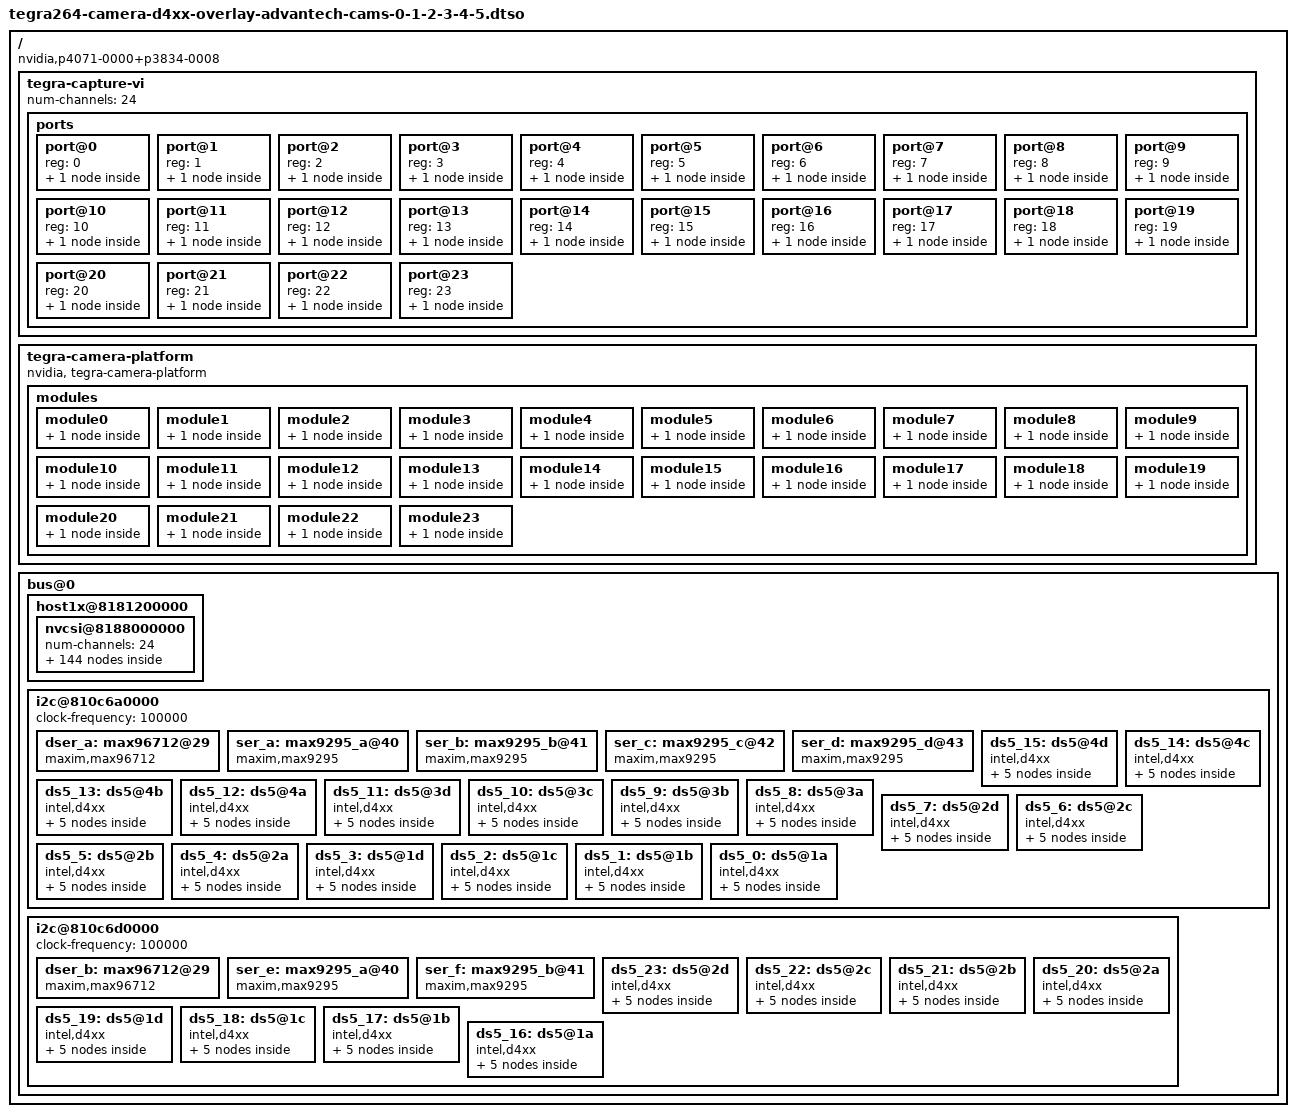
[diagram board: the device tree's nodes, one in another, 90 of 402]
// SPDX-License-Identifier: GPL-2.0-only
// SPDX-FileCopyrightText: Copyright (c) 2018-2023, INTEL CORPORATION.  All rights reserved.

/dts-v1/;
/plugin/;

#include <dt-bindings/gpio/tegra264-gpio.h>

/* camera control gpio definitions */
/ {
	overlay-name = "Jetson six RealSense Cameras D4xx with max96712 Advantech for Thor";
	jetson-header-name = "Jetson AGX CSI Connector";
	compatible = "nvidia,p4071-0000+p3834-0008", "nvidia,p3834-0008", "nvidia,tegra264";

	fragment@0 {
		target-path = "/";
		__overlay__ {
			tegra-capture-vi {
				num-channels = <24>;
				ports {
					status = "okay";
					/* ---- Cameras 0-3 (i2c9 / dser_a) ---- */
					port@0 {
						status = "okay";
						reg = <0>;
						d4xx_vi_in0: endpoint {
							status = "okay";
							vc-id = <0>;
							port-index = <0>;
							bus-width = <2>;
							remote-endpoint = <&d4xx_csi_out0>;
						};
					};
					port@1 {
						status = "okay";
						reg = <1>;
						d4xx_vi_in1: endpoint {
							status = "okay";
							vc-id = <1>;
							port-index = <0>;
							bus-width = <2>;
							remote-endpoint = <&d4xx_csi_out1>;
						};
					};
					port@2 {
						status = "okay";
						reg = <2>;
						d4xx_vi_in2: endpoint {
							status = "okay";
							vc-id = <2>;
							port-index = <0>;
							bus-width = <2>;
							remote-endpoint = <&d4xx_csi_out2>;
						};
					};
					port@3 {
						status = "okay";
						reg = <3>;
						d4xx_vi_in3: endpoint {
							status = "okay";
							vc-id = <3>;
							port-index = <0>;
							bus-width = <2>;
							remote-endpoint = <&d4xx_csi_out3>;
						};
					};
					port@4 {
						status = "okay";
						reg = <4>;
						d4xx_vi_in4: endpoint {
							status = "okay";
							vc-id = <4>;
							port-index = <0>;
							bus-width = <2>;
							remote-endpoint = <&d4xx_csi_out4>;
						};
					};
					port@5 {
						status = "okay";
						reg = <5>;
						d4xx_vi_in5: endpoint {
							status = "okay";
							vc-id = <5>;
							port-index = <0>;
							bus-width = <2>;
							remote-endpoint = <&d4xx_csi_out5>;
						};
					};
					port@6 {
						status = "okay";
						reg = <6>;
						d4xx_vi_in6: endpoint {
							status = "okay";
							vc-id = <6>;
							port-index = <0>;
							bus-width = <2>;
							remote-endpoint = <&d4xx_csi_out6>;
						};
					};
					port@7 {
						status = "okay";
						reg = <7>;
						d4xx_vi_in7: endpoint {
							status = "okay";
							vc-id = <7>;
							port-index = <0>;
							bus-width = <2>;
							remote-endpoint = <&d4xx_csi_out7>;
						};
					};
					port@8 {
						status = "okay";
						reg = <8>;
						d4xx_vi_in8: endpoint {
							status = "okay";
							vc-id = <8>;
							port-index = <0>;
							bus-width = <2>;
							remote-endpoint = <&d4xx_csi_out8>;
						};
					};
					port@9 {
						status = "okay";
						reg = <9>;
						d4xx_vi_in9: endpoint {
							status = "okay";
							vc-id = <9>;
							port-index = <0>;
							bus-width = <2>;
							remote-endpoint = <&d4xx_csi_out9>;
						};
					};
					port@10 {
						status = "okay";
						reg = <10>;
						d4xx_vi_in10: endpoint {
							status = "okay";
							vc-id = <10>;
							port-index = <0>;
							bus-width = <2>;
							remote-endpoint = <&d4xx_csi_out10>;
						};
					};
					port@11 {
						status = "okay";
						reg = <11>;
						d4xx_vi_in11: endpoint {
							status = "okay";
							vc-id = <11>;
							port-index = <0>;
							bus-width = <2>;
							remote-endpoint = <&d4xx_csi_out11>;
						};
					};
					port@12 {
						status = "okay";
						reg = <12>;
						d4xx_vi_in12: endpoint {
							status = "okay";
							vc-id = <12>;
							port-index = <0>;
							bus-width = <2>;
							remote-endpoint = <&d4xx_csi_out12>;
						};
					};
					port@13 {
						status = "okay";
						reg = <13>;
						d4xx_vi_in13: endpoint {
							status = "okay";
							vc-id = <13>;
							port-index = <0>;
							bus-width = <2>;
							remote-endpoint = <&d4xx_csi_out13>;
						};
					};
					port@14 {
						status = "okay";
						reg = <14>;
						d4xx_vi_in14: endpoint {
							status = "okay";
							vc-id = <14>;
							port-index = <0>;
							bus-width = <2>;
							remote-endpoint = <&d4xx_csi_out14>;
						};
					};
					port@15 {
						status = "okay";
						reg = <15>;
						d4xx_vi_in15: endpoint {
							status = "okay";
							vc-id = <15>;
							port-index = <0>;
							bus-width = <2>;
							remote-endpoint = <&d4xx_csi_out15>;
						};
					};
					/* ---- Cameras 4-5 (i2c12 / dser_b) ---- */
					port@16 {
						status = "okay";
						reg = <16>;
						d4xx_vi_in16: endpoint {
							status = "okay";
							vc-id = <0>;
							port-index = <4>;
							bus-width = <2>;
							remote-endpoint = <&d4xx_csi_out16>;
						};
					};
					port@17 {
						status = "okay";
						reg = <17>;
						d4xx_vi_in17: endpoint {
							status = "okay";
							vc-id = <1>;
							port-index = <4>;
							bus-width = <2>;
							remote-endpoint = <&d4xx_csi_out17>;
						};
					};
					port@18 {
						status = "okay";
						reg = <18>;
						d4xx_vi_in18: endpoint {
							status = "okay";
							vc-id = <2>;
							port-index = <4>;
							bus-width = <2>;
							remote-endpoint = <&d4xx_csi_out18>;
						};
					};
					port@19 {
						status = "okay";
						reg = <19>;
						d4xx_vi_in19: endpoint {
							status = "okay";
							vc-id = <3>;
							port-index = <4>;
							bus-width = <2>;
							remote-endpoint = <&d4xx_csi_out19>;
						};
					};
					port@20 {
						status = "okay";
						reg = <20>;
						d4xx_vi_in20: endpoint {
							status = "okay";
							vc-id = <4>;
							port-index = <4>;
							bus-width = <2>;
							remote-endpoint = <&d4xx_csi_out20>;
						};
					};
					port@21 {
						status = "okay";
						reg = <21>;
						d4xx_vi_in21: endpoint {
							status = "okay";
							vc-id = <5>;
							port-index = <4>;
							bus-width = <2>;
							remote-endpoint = <&d4xx_csi_out21>;
						};
					};
					port@22 {
						status = "okay";
						reg = <22>;
						d4xx_vi_in22: endpoint {
							status = "okay";
							vc-id = <6>;
							port-index = <4>;
							bus-width = <2>;
							remote-endpoint = <&d4xx_csi_out22>;
						};
					};
					port@23 {
						status = "okay";
						reg = <23>;
						d4xx_vi_in23: endpoint {
							status = "okay";
							vc-id = <7>;
							port-index = <4>;
							bus-width = <2>;
							remote-endpoint = <&d4xx_csi_out23>;
						};
					};
				};
			};
			tegra-camera-platform {
				compatible = "nvidia, tegra-camera-platform";
				status = "okay";
				num_csi_lanes = <2>;
				max_lane_speed = <1500000>;
				min_bits_per_pixel = <8>;
				vi_peak_byte_per_pixel = <2>;
				vi_bw_margin_pct = <25>;
				max_pixel_rate = <160000>;
				isp_peak_byte_per_pixel = <5>;
				isp_bw_margin_pct = <25>;
				modules {
					status = "okay";
					/* ---- Cameras 0-3 (i2c9) ---- */
					module0 {
						status = "okay";
						badge = "d4xx_depth";
						position = "left";
						orientation = "1";
						drivernode0 {
							status = "okay";
							pcl_id = "v4l2_sensor";
							devname = "DS5 mux 9-001a";
							sysfs-device-tree = "/sys/firmware/devicetree/base/bus@0/i2c@810c6a0000/ds5@1a";
						};
					};
					module1 {
						status = "okay";
						badge = "d4xx_rgb";
						position = "left";
						orientation = "1";
						drivernode0 {
							status = "okay";
							pcl_id = "v4l2_sensor";
							devname = "DS5 mux 9-001b";
							sysfs-device-tree = "/sys/firmware/devicetree/base/bus@0/i2c@810c6a0000/ds5@1b";
						};
					};
					module2 {
						status = "okay";
						badge = "d4xx_Y8";
						position = "left";
						orientation = "1";
						drivernode0 {
							status = "okay";
							pcl_id = "v4l2_sensor";
							devname = "DS5 mux 9-001c";
							sysfs-device-tree = "/sys/firmware/devicetree/base/bus@0/i2c@810c6a0000/ds5@1c";
						};
					};
					module3 {
						status = "okay";
						badge = "d4xx_imu";
						position = "left";
						orientation = "1";
						drivernode0 {
							status = "okay";
							pcl_id = "v4l2_sensor";
							devname = "DS5 mux 9-001d";
							sysfs-device-tree = "/sys/firmware/devicetree/base/bus@0/i2c@810c6a0000/ds5@1d";
						};
					};
					module4 {
						status = "okay";
						badge = "d4xx_depth";
						position = "center";
						orientation = "1";
						drivernode0 {
							status = "okay";
							pcl_id = "v4l2_sensor";
							devname = "DS5 mux 9-002a";
							sysfs-device-tree = "/sys/firmware/devicetree/base/bus@0/i2c@810c6a0000/ds5@2a";
						};
					};
					module5 {
						status = "okay";
						badge = "d4xx_rgb";
						position = "center";
						orientation = "1";
						drivernode0 {
							status = "okay";
							pcl_id = "v4l2_sensor";
							devname = "DS5 mux 9-002b";
							sysfs-device-tree = "/sys/firmware/devicetree/base/bus@0/i2c@810c6a0000/ds5@2b";
						};
					};
					module6 {
						status = "okay";
						badge = "d4xx_Y8";
						position = "center";
						orientation = "1";
						drivernode0 {
							status = "okay";
							pcl_id = "v4l2_sensor";
							devname = "DS5 mux 9-002c";
							sysfs-device-tree = "/sys/firmware/devicetree/base/bus@0/i2c@810c6a0000/ds5@2c";
						};
					};
					module7 {
						status = "okay";
						badge = "d4xx_imu";
						position = "center";
						orientation = "1";
						drivernode0 {
							status = "okay";
							pcl_id = "v4l2_sensor";
							devname = "DS5 mux 9-002d";
							sysfs-device-tree = "/sys/firmware/devicetree/base/bus@0/i2c@810c6a0000/ds5@2d";
						};
					};
					module8 {
						status = "okay";
						badge = "d4xx_depth";
						position = "right";
						orientation = "1";
						drivernode0 {
							status = "okay";
							pcl_id = "v4l2_sensor";
							devname = "DS5 mux 9-003a";
							sysfs-device-tree = "/sys/firmware/devicetree/base/bus@0/i2c@810c6a0000/ds5@3a";
						};
					};
					module9 {
						status = "okay";
						badge = "d4xx_rgb";
						position = "right";
						orientation = "1";
						drivernode0 {
							status = "okay";
							pcl_id = "v4l2_sensor";
							devname = "DS5 mux 9-003b";
							sysfs-device-tree = "/sys/firmware/devicetree/base/bus@0/i2c@810c6a0000/ds5@3b";
						};
					};
					module10 {
						status = "okay";
						badge = "d4xx_Y8";
						position = "right";
						orientation = "1";
						drivernode0 {
							status = "okay";
							pcl_id = "v4l2_sensor";
							devname = "DS5 mux 9-003c";
							sysfs-device-tree = "/sys/firmware/devicetree/base/bus@0/i2c@810c6a0000/ds5@3c";
						};
					};
					module11 {
						status = "okay";
						badge = "d4xx_imu";
						position = "right";
						orientation = "1";
						drivernode0 {
							status = "okay";
							pcl_id = "v4l2_sensor";
							devname = "DS5 mux 9-003d";
							sysfs-device-tree = "/sys/firmware/devicetree/base/bus@0/i2c@810c6a0000/ds5@3d";
						};
					};
					module12 {
						status = "okay";
						badge = "d4xx_depth";
						position = "rear";
						orientation = "1";
						drivernode0 {
							status = "okay";
							pcl_id = "v4l2_sensor";
							devname = "DS5 mux 9-004a";
							sysfs-device-tree = "/sys/firmware/devicetree/base/bus@0/i2c@810c6a0000/ds5@4a";
						};
					};
					module13 {
						status = "okay";
						badge = "d4xx_rgb";
						position = "rear";
						orientation = "1";
						drivernode0 {
							status = "okay";
							pcl_id = "v4l2_sensor";
							devname = "DS5 mux 9-004b";
							sysfs-device-tree = "/sys/firmware/devicetree/base/bus@0/i2c@810c6a0000/ds5@4b";
						};
					};
					module14 {
						status = "okay";
						badge = "d4xx_Y8";
						position = "rear";
						orientation = "1";
						drivernode0 {
							status = "okay";
							pcl_id = "v4l2_sensor";
							devname = "DS5 mux 9-004c";
							sysfs-device-tree = "/sys/firmware/devicetree/base/bus@0/i2c@810c6a0000/ds5@4c";
						};
					};
					module15 {
						status = "okay";
						badge = "d4xx_imu";
						position = "rear";
						orientation = "1";
						drivernode0 {
							status = "okay";
							pcl_id = "v4l2_sensor";
							devname = "DS5 mux 9-004d";
							sysfs-device-tree = "/sys/firmware/devicetree/base/bus@0/i2c@810c6a0000/ds5@4d";
						};
					};
					/* ---- Cameras 4-5 (i2c12) ---- */
					module16 {
						status = "okay";
						badge = "d4xx_depth";
						position = "front-left";
						orientation = "1";
						drivernode0 {
							status = "okay";
							pcl_id = "v4l2_sensor";
							devname = "DS5 mux 12-001a";
							sysfs-device-tree = "/sys/firmware/devicetree/base/bus@0/i2c@810c6d0000/ds5@1a";
						};
					};
					module17 {
						status = "okay";
						badge = "d4xx_rgb";
						position = "front-left";
						orientation = "1";
						drivernode0 {
							status = "okay";
							pcl_id = "v4l2_sensor";
							devname = "DS5 mux 12-001b";
							sysfs-device-tree = "/sys/firmware/devicetree/base/bus@0/i2c@810c6d0000/ds5@1b";
						};
					};
					module18 {
						status = "okay";
						badge = "d4xx_Y8";
						position = "front-left";
						orientation = "1";
						drivernode0 {
							status = "okay";
							pcl_id = "v4l2_sensor";
							devname = "DS5 mux 12-001c";
							sysfs-device-tree = "/sys/firmware/devicetree/base/bus@0/i2c@810c6d0000/ds5@1c";
						};
					};
					module19 {
						status = "okay";
						badge = "d4xx_imu";
						position = "front-left";
						orientation = "1";
						drivernode0 {
							status = "okay";
							pcl_id = "v4l2_sensor";
							devname = "DS5 mux 12-001d";
							sysfs-device-tree = "/sys/firmware/devicetree/base/bus@0/i2c@810c6d0000/ds5@1d";
						};
					};
					module20 {
						status = "okay";
						badge = "d4xx_depth";
						position = "front-right";
						orientation = "1";
						drivernode0 {
							status = "okay";
							pcl_id = "v4l2_sensor";
							devname = "DS5 mux 12-002a";
							sysfs-device-tree = "/sys/firmware/devicetree/base/bus@0/i2c@810c6d0000/ds5@2a";
						};
					};
					module21 {
						status = "okay";
						badge = "d4xx_rgb";
						position = "front-right";
						orientation = "1";
						drivernode0 {
							status = "okay";
							pcl_id = "v4l2_sensor";
							devname = "DS5 mux 12-002b";
							sysfs-device-tree = "/sys/firmware/devicetree/base/bus@0/i2c@810c6d0000/ds5@2b";
						};
					};
					module22 {
						status = "okay";
						badge = "d4xx_Y8";
						position = "front-right";
						orientation = "1";
						drivernode0 {
							status = "okay";
							pcl_id = "v4l2_sensor";
							devname = "DS5 mux 12-002c";
							sysfs-device-tree = "/sys/firmware/devicetree/base/bus@0/i2c@810c6d0000/ds5@2c";
						};
					};
					module23 {
						status = "okay";
						badge = "d4xx_imu";
						position = "front-right";
						orientation = "1";
						drivernode0 {
							status = "okay";
							pcl_id = "v4l2_sensor";
							devname = "DS5 mux 12-002d";
							sysfs-device-tree = "/sys/firmware/devicetree/base/bus@0/i2c@810c6d0000/ds5@2d";
						};
					};
				};
			};
			bus@0 {
				host1x@8181200000 {
					nvcsi@8188000000 {
						num-channels = <24>;
						/* ---- Cameras 0-3 (i2c9 / dser_a) ---- */
						channel@0 {
							status = "okay";
							reg = <0>;
							ports {
								status = "okay";
								port@0 {
									status = "okay";
									reg = <0>;
									d4xx_csi_in0: endpoint@0 {
										status = "okay";
										port-index = <0>;
										bus-width = <2>;
										remote-endpoint = <&ds5_0_out>;
									};
								};
								port@1 {
									status = "okay";
									reg = <1>;
									d4xx_csi_out0: endpoint@1 {
										status = "okay";
										remote-endpoint = <&d4xx_vi_in0>;
									};
								};
							};
						};
						channel@1 {
							status = "okay";
							reg = <1>;
							ports {
								status = "okay";
								port@0 {
									status = "okay";
									reg = <0>;
									d4xx_csi_in1: endpoint@2 {
										status = "okay";
										port-index = <0>;
										bus-width = <2>;
										remote-endpoint = <&ds5_1_out>;
									};
								};
								port@1 {
									status = "okay";
									reg = <1>;
									d4xx_csi_out1: endpoint@3 {
										status = "okay";
										remote-endpoint = <&d4xx_vi_in1>;
									};
								};
							};
						};
						channel@2 {
							status = "okay";
							reg = <2>;
							ports {
								status = "okay";
								port@0 {
									status = "okay";
									reg = <0>;
									d4xx_csi_in2: endpoint@4 {
										status = "okay";
										port-index = <0>;
										bus-width = <2>;
										remote-endpoint = <&ds5_2_out>;
									};
								};
								port@1 {
									status = "okay";
									reg = <1>;
									d4xx_csi_out2: endpoint@5 {
										status = "okay";
										remote-endpoint = <&d4xx_vi_in2>;
									};
								};
							};
						};
						channel@3 {
							status = "okay";
							reg = <3>;
							ports {
								status = "okay";
								port@0 {
									status = "okay";
									reg = <0>;
									d4xx_csi_in3: endpoint@6 {
										status = "okay";
										port-index = <0>;
										bus-width = <2>;
										remote-endpoint = <&ds5_3_out>;
									};
								};
								port@1 {
									status = "okay";
									reg = <1>;
									d4xx_csi_out3: endpoint@7 {
										status = "okay";
										remote-endpoint = <&d4xx_vi_in3>;
									};
								};
							};
						};
						channel@4 {
							status = "okay";
							reg = <4>;
							ports {
								status = "okay";
								port@0 {
									status = "okay";
									reg = <0>;
									d4xx_csi_in4: endpoint@8 {
										status = "okay";
										port-index = <0>;
										bus-width = <2>;
										remote-endpoint = <&ds5_4_out>;
									};
								};
								port@1 {
									status = "okay";
									reg = <1>;
									d4xx_csi_out4: endpoint@9 {
										status = "okay";
										remote-endpoint = <&d4xx_vi_in4>;
									};
								};
							};
						};
						channel@5 {
							status = "okay";
							reg = <5>;
							ports {
								status = "okay";
								port@0 {
									status = "okay";
									reg = <0>;
									d4xx_csi_in5: endpoint@10 {
										status = "okay";
										port-index = <0>;
										bus-width = <2>;
										remote-endpoint = <&ds5_5_out>;
									};
								};
								port@1 {
									status = "okay";
									reg = <1>;
									d4xx_csi_out5: endpoint@11 {
										status = "okay";
										remote-endpoint = <&d4xx_vi_in5>;
									};
								};
							};
						};
						channel@6 {
							status = "okay";
							reg = <6>;
							ports {
								status = "okay";
								port@0 {
									status = "okay";
									reg = <0>;
									d4xx_csi_in6: endpoint@12 {
										status = "okay";
										port-index = <0>;
										bus-width = <2>;
										remote-endpoint = <&ds5_6_out>;
									};
								};
								port@1 {
									status = "okay";
									reg = <1>;
									d4xx_csi_out6: endpoint@13 {
										status = "okay";
										remote-endpoint = <&d4xx_vi_in6>;
									};
								};
							};
						};
						channel@7 {
							status = "okay";
							reg = <7>;
							ports {
								status = "okay";
								port@0 {
									status = "okay";
									reg = <0>;
									d4xx_csi_in7: endpoint@14 {
										status = "okay";
										port-index = <0>;
										bus-width = <2>;
										remote-endpoint = <&ds5_7_out>;
									};
								};
								port@1 {
									status = "okay";
									reg = <1>;
									d4xx_csi_out7: endpoint@15 {
										status = "okay";
										remote-endpoint = <&d4xx_vi_in7>;
									};
								};
							};
						};
						channel@8 {
							status = "okay";
							reg = <8>;
							ports {
								status = "okay";
								port@0 {
									status = "okay";
									reg = <0>;
									d4xx_csi_in8: endpoint@16 {
										status = "okay";
										port-index = <0>;
										bus-width = <2>;
										remote-endpoint = <&ds5_8_out>;
									};
								};
								port@1 {
									status = "okay";
									reg = <1>;
									d4xx_csi_out8: endpoint@17 {
										status = "okay";
										remote-endpoint = <&d4xx_vi_in8>;
									};
								};
							};
						};
						channel@9 {
							status = "okay";
							reg = <9>;
							ports {
								status = "okay";
								port@0 {
									status = "okay";
									reg = <0>;
									d4xx_csi_in9: endpoint@18 {
										status = "okay";
										port-index = <0>;
										bus-width = <2>;
										remote-endpoint = <&ds5_9_out>;
									};
								};
								port@1 {
									status = "okay";
									reg = <1>;
									d4xx_csi_out9: endpoint@19 {
										status = "okay";
										remote-endpoint = <&d4xx_vi_in9>;
									};
								};
							};
						};
						channel@10 {
							status = "okay";
							reg = <10>;
							ports {
								status = "okay";
								port@0 {
									status = "okay";
									reg = <0>;
									d4xx_csi_in10: endpoint@20 {
										status = "okay";
										port-index = <0>;
										bus-width = <2>;
										remote-endpoint = <&ds5_10_out>;
									};
								};
								port@1 {
									status = "okay";
									reg = <1>;
									d4xx_csi_out10: endpoint@21 {
										status = "okay";
										remote-endpoint = <&d4xx_vi_in10>;
									};
								};
							};
						};
						channel@11 {
							status = "okay";
							reg = <11>;
							ports {
								status = "okay";
								port@0 {
									status = "okay";
									reg = <0>;
									d4xx_csi_in11: endpoint@22 {
										status = "okay";
										port-index = <0>;
										bus-width = <2>;
										remote-endpoint = <&ds5_11_out>;
									};
								};
								port@1 {
									status = "okay";
									reg = <1>;
									d4xx_csi_out11: endpoint@23 {
										status = "okay";
										remote-endpoint = <&d4xx_vi_in11>;
									};
								};
							};
						};
						channel@12 {
							status = "okay";
							reg = <12>;
							ports {
								status = "okay";
								port@0 {
									status = "okay";
									reg = <0>;
									d4xx_csi_in12: endpoint@24 {
										status = "okay";
										port-index = <0>;
										bus-width = <2>;
										remote-endpoint = <&ds5_12_out>;
									};
								};
								port@1 {
									status = "okay";
									reg = <1>;
									d4xx_csi_out12: endpoint@25 {
										status = "okay";
										remote-endpoint = <&d4xx_vi_in12>;
									};
								};
							};
						};
						channel@13 {
							status = "okay";
							reg = <13>;
							ports {
								status = "okay";
								port@0 {
									status = "okay";
									reg = <0>;
									d4xx_csi_in13: endpoint@26 {
										status = "okay";
										port-index = <0>;
										bus-width = <2>;
										remote-endpoint = <&ds5_13_out>;
									};
								};
								port@1 {
									status = "okay";
									reg = <1>;
									d4xx_csi_out13: endpoint@27 {
										status = "okay";
										remote-endpoint = <&d4xx_vi_in13>;
									};
								};
							};
						};
						channel@14 {
							status = "okay";
							reg = <14>;
							ports {
								status = "okay";
								port@0 {
									status = "okay";
									reg = <0>;
									d4xx_csi_in14: endpoint@28 {
										status = "okay";
										port-index = <0>;
										bus-width = <2>;
										remote-endpoint = <&ds5_14_out>;
									};
								};
								port@1 {
									status = "okay";
									reg = <1>;
									d4xx_csi_out14: endpoint@29 {
										status = "okay";
										remote-endpoint = <&d4xx_vi_in14>;
									};
								};
							};
						};
						channel@15 {
							status = "okay";
							reg = <15>;
							ports {
								status = "okay";
								port@0 {
									status = "okay";
									reg = <0>;
									d4xx_csi_in15: endpoint@30 {
										status = "okay";
										port-index = <0>;
										bus-width = <2>;
										remote-endpoint = <&ds5_15_out>;
									};
								};
								port@1 {
									status = "okay";
									reg = <1>;
									d4xx_csi_out15: endpoint@31 {
										status = "okay";
										remote-endpoint = <&d4xx_vi_in15>;
									};
								};
							};
						};
						/* ---- Cameras 4-5 (i2c12 / dser_b) ---- */
						channel@16 {
							status = "okay";
							reg = <16>;
							ports {
								status = "okay";
								port@0 {
									status = "okay";
									reg = <0>;
									d4xx_csi_in16: endpoint@32 {
										status = "okay";
										port-index = <4>;
										bus-width = <2>;
										remote-endpoint = <&ds5_16_out>;
									};
								};
								port@1 {
									status = "okay";
									reg = <1>;
									d4xx_csi_out16: endpoint@33 {
										status = "okay";
										remote-endpoint = <&d4xx_vi_in16>;
									};
								};
							};
						};
						channel@17 {
							status = "okay";
							reg = <17>;
							ports {
								status = "okay";
								port@0 {
									status = "okay";
									reg = <0>;
									d4xx_csi_in17: endpoint@34 {
										status = "okay";
										port-index = <4>;
										bus-width = <2>;
										remote-endpoint = <&ds5_17_out>;
									};
								};
								port@1 {
									status = "okay";
									reg = <1>;
									d4xx_csi_out17: endpoint@35 {
										status = "okay";
										remote-endpoint = <&d4xx_vi_in17>;
									};
								};
							};
						};
						channel@18 {
							status = "okay";
							reg = <18>;
							ports {
								status = "okay";
								port@0 {
									status = "okay";
									reg = <0>;
									d4xx_csi_in18: endpoint@36 {
										status = "okay";
										port-index = <4>;
										bus-width = <2>;
										remote-endpoint = <&ds5_18_out>;
									};
								};
								port@1 {
									status = "okay";
									reg = <1>;
									d4xx_csi_out18: endpoint@37 {
										status = "okay";
										remote-endpoint = <&d4xx_vi_in18>;
									};
								};
							};
						};
						channel@19 {
							status = "okay";
							reg = <19>;
							ports {
								status = "okay";
								port@0 {
									status = "okay";
									reg = <0>;
									d4xx_csi_in19: endpoint@38 {
										status = "okay";
										port-index = <4>;
										bus-width = <2>;
										remote-endpoint = <&ds5_19_out>;
									};
								};
								port@1 {
									status = "okay";
									reg = <1>;
									d4xx_csi_out19: endpoint@39 {
										status = "okay";
										remote-endpoint = <&d4xx_vi_in19>;
									};
								};
							};
						};
						channel@20 {
							status = "okay";
							reg = <20>;
							ports {
								status = "okay";
								port@0 {
									status = "okay";
									reg = <0>;
									d4xx_csi_in20: endpoint@40 {
										status = "okay";
										port-index = <4>;
										bus-width = <2>;
										remote-endpoint = <&ds5_20_out>;
									};
								};
								port@1 {
									status = "okay";
									reg = <1>;
									d4xx_csi_out20: endpoint@41 {
										status = "okay";
										remote-endpoint = <&d4xx_vi_in20>;
									};
								};
							};
						};
						channel@21 {
							status = "okay";
							reg = <21>;
							ports {
								status = "okay";
								port@0 {
									status = "okay";
									reg = <0>;
									d4xx_csi_in21: endpoint@42 {
										status = "okay";
										port-index = <4>;
										bus-width = <2>;
										remote-endpoint = <&ds5_21_out>;
									};
								};
								port@1 {
									status = "okay";
									reg = <1>;
									d4xx_csi_out21: endpoint@43 {
										status = "okay";
										remote-endpoint = <&d4xx_vi_in21>;
									};
								};
							};
						};
						channel@22 {
							status = "okay";
							reg = <22>;
							ports {
								status = "okay";
								port@0 {
									status = "okay";
									reg = <0>;
									d4xx_csi_in22: endpoint@44 {
										status = "okay";
										port-index = <4>;
										bus-width = <2>;
										remote-endpoint = <&ds5_22_out>;
									};
								};
								port@1 {
									status = "okay";
									reg = <1>;
									d4xx_csi_out22: endpoint@45 {
										status = "okay";
										remote-endpoint = <&d4xx_vi_in22>;
									};
								};
							};
						};
						channel@23 {
							status = "okay";
							reg = <23>;
							ports {
								status = "okay";
								port@0 {
									status = "okay";
									reg = <0>;
									d4xx_csi_in23: endpoint@46 {
										status = "okay";
										port-index = <4>;
										bus-width = <2>;
										remote-endpoint = <&ds5_23_out>;
									};
								};
								port@1 {
									status = "okay";
									reg = <1>;
									d4xx_csi_out23: endpoint@47 {
										status = "okay";
										remote-endpoint = <&d4xx_vi_in23>;
									};
								};
							};
						};
					};
				};

				/* ---- First deserializer: cameras 0-3 on i2c9 ---- */
				i2c@810c6a0000 {
					clock-frequency = <100000>;

					dser_a: max96712@29 {
						status = "okay";
						reg = <0x29>;
						compatible = "maxim,max96712";
						csi-mode = "2x4";
						link-mask = <0xf>;
						channel = "a";
						force_clk0;
					};

					ser_a: max9295_a@40 {
						status = "okay";
						compatible = "maxim,max9295";
						reg = <0x40>;
						maxim,gmsl-dser-device = <&dser_a>;
						external_addr_reassign;
					};

					ser_b: max9295_b@41 {
						status = "okay";
						compatible = "maxim,max9295";
						reg = <0x41>;
						maxim,gmsl-dser-device = <&dser_a>;
						external_addr_reassign;
					};

					ser_c: max9295_c@42 {
						status = "okay";
						compatible = "maxim,max9295";
						reg = <0x42>;
						maxim,gmsl-dser-device = <&dser_a>;
						external_addr_reassign;
					};

					ser_d: max9295_d@43 {
						status = "okay";
						compatible = "maxim,max9295";
						reg = <0x43>;
						maxim,gmsl-dser-device = <&dser_a>;
						external_addr_reassign;
					};

					ds5_15: ds5@4d {
						status = "okay";
						def-addr = <0x10>;
						reg = <0x4d>;
						override_reg = <0x4a>;
						compatible = "intel,d4xx";
						use_sensor_mode_id = "true";
						cam-type = "IMU";
						nvidia,gmsl-ser-device = <&ser_d>;
						nvidia,gmsl-dser-device = <&dser_a>;
						ports {
							#address-cells = <1>;
							#size-cells = <0>;

							port@0 {
								reg = <0>;
								ds5_15_out: endpoint {
									vc-id = <15>;
									port-index = <15>;
									bus-width = <2>;
									remote-endpoint = <&d4xx_csi_in15>;
								};
							};
						};
						mode0 {
							pixel_t = "grey_y16";
							num_lanes = "2";
							csi_pixel_bit_depth = "16";
							active_w = "640";
							active_h = "480";
							tegra_sinterface = "serial_b";
							mclk_khz = "24000";
							pix_clk_hz = "74250000";
							line_length = "1280"; /* 2200 */
							embedded_metadata_height = "0";
						};
						gmsl-link {
							src-csi-port = "b";
							dst-csi-port = "a";
							serdes-csi-link = "a";
							csi-mode = "1x4";
							st-vc = <0>;
							vc-id = <15>;
							num-lanes = <2>;
						};
					};

					ds5_14: ds5@4c {
						status = "okay";
						def-addr = <0x10>;
						reg = <0x4c>;
						override_reg = <0x4a>;
						compatible = "intel,d4xx";
						use_sensor_mode_id = "true";
						cam-type = "Y8";
						nvidia,gmsl-ser-device = <&ser_d>;
						nvidia,gmsl-dser-device = <&dser_a>;
						ports {
							#address-cells = <1>;
							#size-cells = <0>;

							port@0 {
								reg = <0>;
								ds5_14_out: endpoint {
									vc-id = <14>;
									port-index = <14>;
									bus-width = <2>;
									remote-endpoint = <&d4xx_csi_in14>;
								};
							};
						};
						/* mode0: Y8, mode1: depth D16 */
						mode0 {
							pixel_t = "grey_y16";
							num_lanes = "2";
							csi_pixel_bit_depth = "16";
							active_w = "1280";
							active_h = "720";
							tegra_sinterface = "serial_b";
							mclk_khz = "24000";
							pix_clk_hz = "74250000";
							line_length = "1280"; /* 2200 */
							embedded_metadata_height = "1";
						};
						gmsl-link {
							src-csi-port = "b";
							dst-csi-port = "a";
							serdes-csi-link = "a";
							csi-mode = "1x4";
							st-vc = <0>;
							vc-id = <14>;
							num-lanes = <2>;
						};
					};

					ds5_13: ds5@4b {
						status = "okay";
						def-addr = <0x10>;
						reg = <0x4b>;
						override_reg = <0x4a>;
						compatible = "intel,d4xx";
						use_sensor_mode_id = "true";
						cam-type = "RGB";
						nvidia,gmsl-ser-device = <&ser_d>;
						nvidia,gmsl-dser-device = <&dser_a>;
						ports {
							#address-cells = <1>;
							#size-cells = <0>;

							port@0 {
								reg = <0>;
								ds5_13_out: endpoint {
									vc-id = <13>;
									port-index = <13>;
									bus-width = <2>;
									remote-endpoint = <&d4xx_csi_in13>;
								};
							};
						};
						mode0 {
							pixel_t = "grey_y16";
							num_lanes = "2";
							csi_pixel_bit_depth = "16";
							active_w = "1920";
							active_h = "1080";
							tegra_sinterface = "serial_e";
							mclk_khz = "24000";
							pix_clk_hz = "74250000";
							line_length = "1280"; /* 2200 */
							embedded_metadata_height = "1";
						};
						gmsl-link {
							src-csi-port = "b";
							dst-csi-port = "a";
							serdes-csi-link = "a";
							csi-mode = "1x4";
							st-vc = <0>;
							vc-id = <13>;
							num-lanes = <2>;
						};
					};

					ds5_12: ds5@4a {
						status = "okay";
						def-addr = <0x10>;
						reg = <0x4a>;
						compatible = "intel,d4xx";
						use_sensor_mode_id = "true";
						cam-type = "Depth";
						nvidia,gmsl-ser-device = <&ser_d>;
						nvidia,gmsl-dser-device = <&dser_a>;
						ports {
							#address-cells = <1>;
							#size-cells = <0>;

							port@0 {
								reg = <0>;
								ds5_12_out: endpoint {
									vc-id = <12>;
									port-index = <12>;
									bus-width = <2>;
									remote-endpoint = <&d4xx_csi_in12>;
								};
							};
						};
						mode0 {
							pixel_t = "grey_y16";
							num_lanes = "2";
							csi_pixel_bit_depth = "16";
							active_w = "1280";
							active_h = "720";
							tegra_sinterface = "serial_a";
							mclk_khz = "24000";
							pix_clk_hz = "74250000";
							line_length = "1280"; /* 2200 */
							embedded_metadata_height = "1";
						};
						gmsl-link {
							src-csi-port = "b";
							dst-csi-port = "a";
							serdes-csi-link = "a";
							csi-mode = "1x4";
							st-vc = <0>;
							vc-id = <12>;
							num-lanes = <2>;
						};
					};

					ds5_11: ds5@3d {
						status = "okay";
						def-addr = <0x10>;
						reg = <0x3d>;
						override_reg = <0x3a>;
						compatible = "intel,d4xx";
						use_sensor_mode_id = "true";
						cam-type = "IMU";
						nvidia,gmsl-ser-device = <&ser_c>;
						nvidia,gmsl-dser-device = <&dser_a>;
						ports {
							#address-cells = <1>;
							#size-cells = <0>;

							port@0 {
								reg = <0>;
								ds5_11_out: endpoint {
									vc-id = <11>;
									port-index = <11>;
									bus-width = <2>;
									remote-endpoint = <&d4xx_csi_in11>;
								};
							};
						};
						mode0 {
							pixel_t = "grey_y16";
							num_lanes = "2";
							csi_pixel_bit_depth = "16";
							active_w = "640";
							active_h = "480";
							tegra_sinterface = "serial_b";
							mclk_khz = "24000";
							pix_clk_hz = "74250000";
							line_length = "1280"; /* 2200 */
							embedded_metadata_height = "0";
						};
						gmsl-link {
							src-csi-port = "b";
							dst-csi-port = "a";
							serdes-csi-link = "a";
							csi-mode = "1x4";
							st-vc = <0>;
							vc-id = <11>;
							num-lanes = <2>;
						};
					};

					ds5_10: ds5@3c {
						status = "okay";
						def-addr = <0x10>;
						reg = <0x3c>;
						override_reg = <0x3a>;
						compatible = "intel,d4xx";
						use_sensor_mode_id = "true";
						cam-type = "Y8";
						nvidia,gmsl-ser-device = <&ser_c>;
						nvidia,gmsl-dser-device = <&dser_a>;
						ports {
							#address-cells = <1>;
							#size-cells = <0>;

							port@0 {
								reg = <0>;
								ds5_10_out: endpoint {
									vc-id = <10>;
									port-index = <10>;
									bus-width = <2>;
									remote-endpoint = <&d4xx_csi_in10>;
								};
							};
						};
						/* mode0: Y8, mode1: depth D16 */
						mode0 {
							pixel_t = "grey_y16";
							num_lanes = "2";
							csi_pixel_bit_depth = "16";
							active_w = "1280";
							active_h = "720";
							tegra_sinterface = "serial_b";
							mclk_khz = "24000";
							pix_clk_hz = "74250000";
							line_length = "1280"; /* 2200 */
							embedded_metadata_height = "1";
						};
						gmsl-link {
							src-csi-port = "b";
							dst-csi-port = "a";
							serdes-csi-link = "a";
							csi-mode = "1x4";
							st-vc = <0>;
							vc-id = <10>;
							num-lanes = <2>;
						};
					};

					ds5_9: ds5@3b {
						status = "okay";
						def-addr = <0x10>;
						reg = <0x3b>;
						override_reg = <0x3a>;
						compatible = "intel,d4xx";
						use_sensor_mode_id = "true";
						cam-type = "RGB";
						nvidia,gmsl-ser-device = <&ser_c>;
						nvidia,gmsl-dser-device = <&dser_a>;
						ports {
							#address-cells = <1>;
							#size-cells = <0>;

							port@0 {
								reg = <0>;
								ds5_9_out: endpoint {
									vc-id = <9>;
									port-index = <9>;
									bus-width = <2>;
									remote-endpoint = <&d4xx_csi_in9>;
								};
							};
						};
						mode0 {
							pixel_t = "grey_y16";
							num_lanes = "2";
							csi_pixel_bit_depth = "16";
							active_w = "1920";
							active_h = "1080";
							tegra_sinterface = "serial_e";
							mclk_khz = "24000";
							pix_clk_hz = "74250000";
							line_length = "1280"; /* 2200 */
							embedded_metadata_height = "1";
						};
						gmsl-link {
							src-csi-port = "b";
							dst-csi-port = "a";
							serdes-csi-link = "a";
							csi-mode = "1x4";
							st-vc = <0>;
							vc-id = <9>;
							num-lanes = <2>;
						};
					};

					ds5_8: ds5@3a {
						status = "okay";
						def-addr = <0x10>;
						reg = <0x3a>;
						compatible = "intel,d4xx";
						use_sensor_mode_id = "true";
						cam-type = "Depth";
						nvidia,gmsl-ser-device = <&ser_c>;
						nvidia,gmsl-dser-device = <&dser_a>;
						ports {
							#address-cells = <1>;
							#size-cells = <0>;

							port@0 {
								reg = <0>;
								ds5_8_out: endpoint {
									vc-id = <8>;
									port-index = <8>;
									bus-width = <2>;
									remote-endpoint = <&d4xx_csi_in8>;
								};
							};
						};
						mode0 {
							pixel_t = "grey_y16";
							num_lanes = "2";
							csi_pixel_bit_depth = "16";
							active_w = "1280";
							active_h = "720";
							tegra_sinterface = "serial_a";
							mclk_khz = "24000";
							pix_clk_hz = "74250000";
							line_length = "1280"; /* 2200 */
							embedded_metadata_height = "1";
						};
						gmsl-link {
							src-csi-port = "b";
							dst-csi-port = "a";
							serdes-csi-link = "a";
							csi-mode = "1x4";
							st-vc = <0>;
							vc-id = <8>;
							num-lanes = <2>;
						};
					};

					ds5_7: ds5@2d {
						status = "okay";
						def-addr = <0x10>;
						reg = <0x2d>;
						override_reg = <0x2a>;
						compatible = "intel,d4xx";
						use_sensor_mode_id = "true";
						cam-type = "IMU";
						nvidia,gmsl-ser-device = <&ser_b>;
						nvidia,gmsl-dser-device = <&dser_a>;
						ports {
							#address-cells = <1>;
							#size-cells = <0>;

							port@0 {
								reg = <0>;
								ds5_7_out: endpoint {
									vc-id = <7>;
									port-index = <7>;
									bus-width = <2>;
									remote-endpoint = <&d4xx_csi_in7>;
								};
							};
						};
						mode0 {
							pixel_t = "grey_y16";
							num_lanes = "2";
							csi_pixel_bit_depth = "16";
							active_w = "640";
							active_h = "480";
							tegra_sinterface = "serial_b";
							mclk_khz = "24000";
							pix_clk_hz = "74250000";
							line_length = "1280"; /* 2200 */
							embedded_metadata_height = "0";
						};
						gmsl-link {
							src-csi-port = "b";
							dst-csi-port = "a";
							serdes-csi-link = "a";
							csi-mode = "1x4";
							st-vc = <0>;
							vc-id = <7>;
							num-lanes = <2>;
						};
					};

					ds5_6: ds5@2c {
						status = "okay";
						def-addr = <0x10>;
						reg = <0x2c>;
						override_reg = <0x2a>;
						compatible = "intel,d4xx";
						use_sensor_mode_id = "true";
						cam-type = "Y8";
						nvidia,gmsl-ser-device = <&ser_b>;
						nvidia,gmsl-dser-device = <&dser_a>;
						ports {
							#address-cells = <1>;
							#size-cells = <0>;

							port@0 {
								reg = <0>;
								ds5_6_out: endpoint {
									vc-id = <6>;
									port-index = <6>;
									bus-width = <2>;
									remote-endpoint = <&d4xx_csi_in6>;
								};
							};
						};
						/* mode0: Y8, mode1: depth D16 */
						mode0 {
							pixel_t = "grey_y16";
							num_lanes = "2";
							csi_pixel_bit_depth = "16";
							active_w = "1280";
							active_h = "720";
							tegra_sinterface = "serial_b";
							mclk_khz = "24000";
							pix_clk_hz = "74250000";
							line_length = "1280"; /* 2200 */
							embedded_metadata_height = "1";
						};
						gmsl-link {
							src-csi-port = "b";
							dst-csi-port = "a";
							serdes-csi-link = "a";
							csi-mode = "1x4";
							st-vc = <0>;
							vc-id = <6>;
							num-lanes = <2>;
						};
					};

					ds5_5: ds5@2b {
						status = "okay";
						def-addr = <0x10>;
						reg = <0x2b>;
						override_reg = <0x2a>;
						compatible = "intel,d4xx";
						use_sensor_mode_id = "true";
						cam-type = "RGB";
						nvidia,gmsl-ser-device = <&ser_b>;
						nvidia,gmsl-dser-device = <&dser_a>;
						ports {
							#address-cells = <1>;
							#size-cells = <0>;

							port@0 {
								reg = <0>;
								ds5_5_out: endpoint {
									vc-id = <5>;
									port-index = <5>;
									bus-width = <2>;
									remote-endpoint = <&d4xx_csi_in5>;
								};
							};
						};
						mode0 {
							pixel_t = "grey_y16";
							num_lanes = "2";
							csi_pixel_bit_depth = "16";
							active_w = "1920";
							active_h = "1080";
							tegra_sinterface = "serial_e";
							mclk_khz = "24000";
							pix_clk_hz = "74250000";
							line_length = "1280"; /* 2200 */
							embedded_metadata_height = "1";
						};
						gmsl-link {
							src-csi-port = "b";
							dst-csi-port = "a";
							serdes-csi-link = "a";
							csi-mode = "1x4";
							st-vc = <0>;
							vc-id = <5>;
							num-lanes = <2>;
						};
					};

					ds5_4: ds5@2a {
						status = "okay";
						def-addr = <0x10>;
						reg = <0x2a>;
						compatible = "intel,d4xx";
						use_sensor_mode_id = "true";
						cam-type = "Depth";
						nvidia,gmsl-ser-device = <&ser_b>;
						nvidia,gmsl-dser-device = <&dser_a>;
						ports {
							#address-cells = <1>;
							#size-cells = <0>;

							port@0 {
								reg = <0>;
								ds5_4_out: endpoint {
									vc-id = <4>;
									port-index = <4>;
									bus-width = <2>;
									remote-endpoint = <&d4xx_csi_in4>;
								};
							};
						};
						mode0 {
							pixel_t = "grey_y16";
							num_lanes = "2";
							csi_pixel_bit_depth = "16";
							active_w = "1280";
							active_h = "720";
							tegra_sinterface = "serial_a";
							mclk_khz = "24000";
							pix_clk_hz = "74250000";
							line_length = "1280"; /* 2200 */
							embedded_metadata_height = "1";
						};
						gmsl-link {
							src-csi-port = "b";
							dst-csi-port = "a";
							serdes-csi-link = "a";
							csi-mode = "1x4";
							st-vc = <0>;
							vc-id = <4>;
							num-lanes = <2>;
						};
					};

					ds5_3: ds5@1d {
						status = "okay";
						def-addr = <0x10>;
						reg = <0x1d>;
						override_reg = <0x1a>;
						compatible = "intel,d4xx";
						use_sensor_mode_id = "true";
						cam-type = "IMU";
						nvidia,gmsl-ser-device = <&ser_a>;
						nvidia,gmsl-dser-device = <&dser_a>;
						ports {
							#address-cells = <1>;
							#size-cells = <0>;

							port@0 {
								reg = <0>;
								ds5_3_out: endpoint {
									vc-id = <3>;
									port-index = <3>;
									bus-width = <2>;
									remote-endpoint = <&d4xx_csi_in3>;
								};
							};
						};
						mode0 {
							pixel_t = "grey_y16";
							num_lanes = "2";
							csi_pixel_bit_depth = "16";
							active_w = "640";
							active_h = "480";
							tegra_sinterface = "serial_b";
							mclk_khz = "24000";
							pix_clk_hz = "74250000";
							line_length = "1280"; /* 2200 */
							embedded_metadata_height = "0";
						};
						gmsl-link {
							src-csi-port = "b";
							dst-csi-port = "a";
							serdes-csi-link = "a";
							csi-mode = "1x4";
							st-vc = <0>;
							vc-id = <3>;
							num-lanes = <2>;
						};
					};

					ds5_2: ds5@1c {
						status = "okay";
						def-addr = <0x10>;
						reg = <0x1c>;
						override_reg = <0x1a>;
						compatible = "intel,d4xx";
						use_sensor_mode_id = "true";
						cam-type = "Y8";
						nvidia,gmsl-ser-device = <&ser_a>;
						nvidia,gmsl-dser-device = <&dser_a>;
						ports {
							#address-cells = <1>;
							#size-cells = <0>;

							port@0 {
								reg = <0>;
								ds5_2_out: endpoint {
									vc-id = <2>;
									port-index = <2>;
									bus-width = <2>;
									remote-endpoint = <&d4xx_csi_in2>;
								};
							};
						};
						/* mode0: Y8, mode1: depth D16 */
						mode0 {
							pixel_t = "grey_y16";
							num_lanes = "2";
							csi_pixel_bit_depth = "16";
							active_w = "1280";
							active_h = "720";
							tegra_sinterface = "serial_b";
							mclk_khz = "24000";
							pix_clk_hz = "74250000";
							line_length = "1280"; /* 2200 */
							embedded_metadata_height = "1";
						};
						gmsl-link {
							src-csi-port = "b";
							dst-csi-port = "a";
							serdes-csi-link = "a";
							csi-mode = "1x4";
							st-vc = <0>;
							vc-id = <2>;
							num-lanes = <2>;
						};
					};

					ds5_1: ds5@1b {
						status = "okay";
						def-addr = <0x10>;
						reg = <0x1b>;
						override_reg = <0x1a>;
						compatible = "intel,d4xx";
						use_sensor_mode_id = "true";
						cam-type = "RGB";
						nvidia,gmsl-ser-device = <&ser_a>;
						nvidia,gmsl-dser-device = <&dser_a>;
						ports {
							#address-cells = <1>;
							#size-cells = <0>;

							port@0 {
								reg = <0>;
								ds5_1_out: endpoint {
									vc-id = <1>;
									port-index = <1>;
									bus-width = <2>;
									remote-endpoint = <&d4xx_csi_in1>;
								};
							};
						};
						mode0 {
							pixel_t = "grey_y16";
							num_lanes = "2";
							csi_pixel_bit_depth = "16";
							active_w = "1920";
							active_h = "1080";
							tegra_sinterface = "serial_e";
							mclk_khz = "24000";
							pix_clk_hz = "74250000";
							line_length = "1280"; /* 2200 */
							embedded_metadata_height = "1";
						};
						gmsl-link {
							src-csi-port = "b";
							dst-csi-port = "a";
							serdes-csi-link = "a";
							csi-mode = "1x4";
							st-vc = <0>;
							vc-id = <1>;
							num-lanes = <2>;
						};
					};

					ds5_0: ds5@1a {
						status = "okay";
						def-addr = <0x10>;
						reg = <0x1a>;
						compatible = "intel,d4xx";
						use_sensor_mode_id = "true";
						cam-type = "Depth";
						nvidia,gmsl-ser-device = <&ser_a>;
						nvidia,gmsl-dser-device = <&dser_a>;
						ports {
							#address-cells = <1>;
							#size-cells = <0>;

							port@0 {
								reg = <0>;
								ds5_0_out: endpoint {
									vc-id = <0>;
									port-index = <0>;
									bus-width = <2>;
									remote-endpoint = <&d4xx_csi_in0>;
								};
							};
						};
						mode0 {
							pixel_t = "grey_y16";
							num_lanes = "2";
							csi_pixel_bit_depth = "16";
							active_w = "1280";
							active_h = "720";
							tegra_sinterface = "serial_a";
							mclk_khz = "24000";
							pix_clk_hz = "74250000";
							line_length = "1280"; /* 2200 */
							embedded_metadata_height = "1";
						};
						gmsl-link {
							src-csi-port = "b";
							dst-csi-port = "a";
							serdes-csi-link = "a";
							csi-mode = "1x4";
							st-vc = <0>;
							vc-id = <0>;
							num-lanes = <2>;
						};
					};
				};

				/* ---- Second deserializer: cameras 4-5 on i2c12 ---- */
				i2c@810c6d0000 {
					clock-frequency = <100000>;

					dser_b: max96712@29 {
						status = "okay";
						reg = <0x29>;
						compatible = "maxim,max96712";
						csi-mode = "2x4";
						link-mask = <0x3>;
						channel = "b";
						force_clk0;
					};

					ser_e: max9295_a@40 {
						status = "okay";
						compatible = "maxim,max9295";
						reg = <0x40>;
						maxim,gmsl-dser-device = <&dser_b>;
						external_addr_reassign;
					};

					ser_f: max9295_b@41 {
						status = "okay";
						compatible = "maxim,max9295";
						reg = <0x41>;
						maxim,gmsl-dser-device = <&dser_b>;
						external_addr_reassign;
					};

					ds5_23: ds5@2d {
						status = "okay";
						def-addr = <0x10>;
						reg = <0x2d>;
						override_reg = <0x2a>;
						compatible = "intel,d4xx";
						use_sensor_mode_id = "true";
						cam-type = "IMU";
						nvidia,gmsl-ser-device = <&ser_f>;
						nvidia,gmsl-dser-device = <&dser_b>;
						ports {
							#address-cells = <1>;
							#size-cells = <0>;

							port@0 {
								reg = <0>;
								ds5_23_out: endpoint {
									vc-id = <7>;
									port-index = <23>;
									bus-width = <2>;
									remote-endpoint = <&d4xx_csi_in23>;
								};
							};
						};
						mode0 {
							pixel_t = "grey_y16";
							num_lanes = "2";
							csi_pixel_bit_depth = "16";
							active_w = "640";
							active_h = "480";
							tegra_sinterface = "serial_b";
							mclk_khz = "24000";
							pix_clk_hz = "74250000";
							line_length = "1280"; /* 2200 */
							embedded_metadata_height = "0";
						};
						gmsl-link {
							src-csi-port = "b";
							dst-csi-port = "a";
							serdes-csi-link = "a";
							csi-mode = "1x4";
							st-vc = <0>;
							vc-id = <7>;
							num-lanes = <2>;
						};
					};

					ds5_22: ds5@2c {
						status = "okay";
						def-addr = <0x10>;
						reg = <0x2c>;
						override_reg = <0x2a>;
						compatible = "intel,d4xx";
						use_sensor_mode_id = "true";
						cam-type = "Y8";
						nvidia,gmsl-ser-device = <&ser_f>;
						nvidia,gmsl-dser-device = <&dser_b>;
						ports {
							#address-cells = <1>;
							#size-cells = <0>;

							port@0 {
								reg = <0>;
								ds5_22_out: endpoint {
									vc-id = <6>;
									port-index = <22>;
									bus-width = <2>;
									remote-endpoint = <&d4xx_csi_in22>;
								};
							};
						};
						/* mode0: Y8, mode1: depth D16 */
						mode0 {
							pixel_t = "grey_y16";
							num_lanes = "2";
							csi_pixel_bit_depth = "16";
							active_w = "1280";
							active_h = "720";
							tegra_sinterface = "serial_b";
							mclk_khz = "24000";
							pix_clk_hz = "74250000";
							line_length = "1280"; /* 2200 */
							embedded_metadata_height = "1";
						};
						gmsl-link {
							src-csi-port = "b";
							dst-csi-port = "a";
							serdes-csi-link = "a";
							csi-mode = "1x4";
							st-vc = <0>;
							vc-id = <6>;
							num-lanes = <2>;
						};
					};

					ds5_21: ds5@2b {
						status = "okay";
						def-addr = <0x10>;
						reg = <0x2b>;
						override_reg = <0x2a>;
						compatible = "intel,d4xx";
						use_sensor_mode_id = "true";
						cam-type = "RGB";
						nvidia,gmsl-ser-device = <&ser_f>;
						nvidia,gmsl-dser-device = <&dser_b>;
						ports {
							#address-cells = <1>;
							#size-cells = <0>;

							port@0 {
								reg = <0>;
								ds5_21_out: endpoint {
									vc-id = <5>;
									port-index = <21>;
									bus-width = <2>;
									remote-endpoint = <&d4xx_csi_in21>;
								};
							};
						};
						mode0 {
							pixel_t = "grey_y16";
							num_lanes = "2";
							csi_pixel_bit_depth = "16";
							active_w = "1920";
							active_h = "1080";
							tegra_sinterface = "serial_e";
							mclk_khz = "24000";
							pix_clk_hz = "74250000";
							line_length = "1280"; /* 2200 */
							embedded_metadata_height = "1";
						};
						gmsl-link {
							src-csi-port = "b";
							dst-csi-port = "a";
							serdes-csi-link = "a";
							csi-mode = "1x4";
							st-vc = <0>;
							vc-id = <5>;
							num-lanes = <2>;
						};
					};

					ds5_20: ds5@2a {
						status = "okay";
						def-addr = <0x10>;
						reg = <0x2a>;
						compatible = "intel,d4xx";
						use_sensor_mode_id = "true";
						cam-type = "Depth";
						nvidia,gmsl-ser-device = <&ser_f>;
						nvidia,gmsl-dser-device = <&dser_b>;
						ports {
							#address-cells = <1>;
							#size-cells = <0>;

							port@0 {
								reg = <0>;
								ds5_20_out: endpoint {
									vc-id = <4>;
									port-index = <20>;
									bus-width = <2>;
									remote-endpoint = <&d4xx_csi_in20>;
								};
							};
						};
						mode0 {
							pixel_t = "grey_y16";
							num_lanes = "2";
							csi_pixel_bit_depth = "16";
							active_w = "1280";
							active_h = "720";
							tegra_sinterface = "serial_a";
							mclk_khz = "24000";
							pix_clk_hz = "74250000";
							line_length = "1280"; /* 2200 */
							embedded_metadata_height = "1";
						};
						gmsl-link {
							src-csi-port = "b";
							dst-csi-port = "a";
							serdes-csi-link = "a";
							csi-mode = "1x4";
							st-vc = <0>;
							vc-id = <4>;
							num-lanes = <2>;
						};
					};

					ds5_19: ds5@1d {
						status = "okay";
						def-addr = <0x10>;
						reg = <0x1d>;
						override_reg = <0x1a>;
						compatible = "intel,d4xx";
						use_sensor_mode_id = "true";
						cam-type = "IMU";
						nvidia,gmsl-ser-device = <&ser_e>;
						nvidia,gmsl-dser-device = <&dser_b>;
						ports {
							#address-cells = <1>;
							#size-cells = <0>;

							port@0 {
								reg = <0>;
								ds5_19_out: endpoint {
									vc-id = <3>;
									port-index = <19>;
									bus-width = <2>;
									remote-endpoint = <&d4xx_csi_in19>;
								};
							};
						};
						mode0 {
							pixel_t = "grey_y16";
							num_lanes = "2";
							csi_pixel_bit_depth = "16";
							active_w = "640";
							active_h = "480";
							tegra_sinterface = "serial_b";
							mclk_khz = "24000";
							pix_clk_hz = "74250000";
							line_length = "1280"; /* 2200 */
							embedded_metadata_height = "0";
						};
						gmsl-link {
							src-csi-port = "b";
							dst-csi-port = "a";
							serdes-csi-link = "a";
							csi-mode = "1x4";
							st-vc = <0>;
							vc-id = <3>;
							num-lanes = <2>;
						};
					};

					ds5_18: ds5@1c {
						status = "okay";
						def-addr = <0x10>;
						reg = <0x1c>;
						override_reg = <0x1a>;
						compatible = "intel,d4xx";
						use_sensor_mode_id = "true";
						cam-type = "Y8";
						nvidia,gmsl-ser-device = <&ser_e>;
						nvidia,gmsl-dser-device = <&dser_b>;
						ports {
							#address-cells = <1>;
							#size-cells = <0>;

							port@0 {
								reg = <0>;
								ds5_18_out: endpoint {
									vc-id = <2>;
									port-index = <18>;
									bus-width = <2>;
									remote-endpoint = <&d4xx_csi_in18>;
								};
							};
						};
						/* mode0: Y8, mode1: depth D16 */
						mode0 {
							pixel_t = "grey_y16";
							num_lanes = "2";
							csi_pixel_bit_depth = "16";
							active_w = "1280";
							active_h = "720";
							tegra_sinterface = "serial_b";
							mclk_khz = "24000";
							pix_clk_hz = "74250000";
							line_length = "1280"; /* 2200 */
							embedded_metadata_height = "1";
						};
						gmsl-link {
							src-csi-port = "b";
							dst-csi-port = "a";
							serdes-csi-link = "a";
							csi-mode = "1x4";
							st-vc = <0>;
							vc-id = <2>;
							num-lanes = <2>;
						};
					};

					ds5_17: ds5@1b {
						status = "okay";
						def-addr = <0x10>;
						reg = <0x1b>;
						override_reg = <0x1a>;
						compatible = "intel,d4xx";
						use_sensor_mode_id = "true";
						cam-type = "RGB";
						nvidia,gmsl-ser-device = <&ser_e>;
						nvidia,gmsl-dser-device = <&dser_b>;
						ports {
							#address-cells = <1>;
							#size-cells = <0>;

							port@0 {
								reg = <0>;
								ds5_17_out: endpoint {
									vc-id = <1>;
									port-index = <17>;
									bus-width = <2>;
									remote-endpoint = <&d4xx_csi_in17>;
								};
							};
						};
						mode0 {
							pixel_t = "grey_y16";
							num_lanes = "2";
							csi_pixel_bit_depth = "16";
							active_w = "1920";
							active_h = "1080";
							tegra_sinterface = "serial_e";
							mclk_khz = "24000";
							pix_clk_hz = "74250000";
							line_length = "1280"; /* 2200 */
							embedded_metadata_height = "1";
						};
						gmsl-link {
							src-csi-port = "b";
							dst-csi-port = "a";
							serdes-csi-link = "a";
							csi-mode = "1x4";
							st-vc = <0>;
							vc-id = <1>;
							num-lanes = <2>;
						};
					};

					ds5_16: ds5@1a {
						status = "okay";
						def-addr = <0x10>;
						reg = <0x1a>;
						compatible = "intel,d4xx";
						use_sensor_mode_id = "true";
						cam-type = "Depth";
						nvidia,gmsl-ser-device = <&ser_e>;
						nvidia,gmsl-dser-device = <&dser_b>;
						ports {
							#address-cells = <1>;
							#size-cells = <0>;

							port@0 {
								reg = <0>;
								ds5_16_out: endpoint {
									vc-id = <0>;
									port-index = <16>;
									bus-width = <2>;
									remote-endpoint = <&d4xx_csi_in16>;
								};
							};
						};
						mode0 {
							pixel_t = "grey_y16";
							num_lanes = "2";
							csi_pixel_bit_depth = "16";
							active_w = "1280";
							active_h = "720";
							tegra_sinterface = "serial_a";
							mclk_khz = "24000";
							pix_clk_hz = "74250000";
							line_length = "1280"; /* 2200 */
							embedded_metadata_height = "1";
						};
						gmsl-link {
							src-csi-port = "b";
							dst-csi-port = "a";
							serdes-csi-link = "a";
							csi-mode = "1x4";
							st-vc = <0>;
							vc-id = <0>;
							num-lanes = <2>;
						};
					};
				};
			};
		};
	};
};
